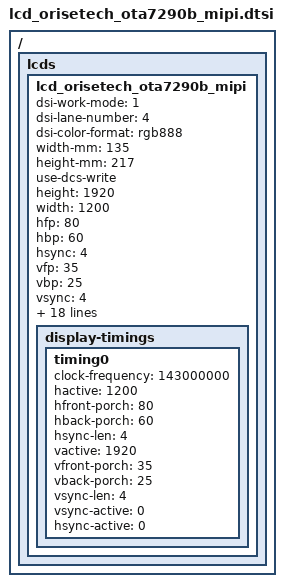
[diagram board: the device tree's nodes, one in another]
// SPDX-License-Identifier: GPL-2.0

/ { lcds: lcds {
	lcd_orisetech_ota7290b_mipi: lcd_orisetech_ota7290b_mipi {
		dsi-work-mode = <1>; /* video burst mode*/
		dsi-lane-number = <4>;
		dsi-color-format = "rgb888";
		width-mm = <135>;
		height-mm = <217>;
		use-dcs-write;

		/*mipi info*/
		height = <1920>;
		width = <1200>;
		hfp = <80>;
		hbp = <60>;
		hsync = <4>;
		vfp = <35>;
		vbp = <25>;
		vsync = <4>;
		fps = <55>;
		work-mode = <0>;
		rgb-mode = <3>;
		lane-number = <4>;
		phy-bit-clock = <1000000000>;
		phy-esc-clock = <76800000>;
		split-enable = <0>;
		eotp-enable = <0>;
		burst-mode = <2>;
		esd-check-enable = <0>;

		/* DSI_CMD, DSI_MODE, timeout, len, cmd */
		initial-command = [
			39 01 F0 01 11
			39 01 28 01 29
		];
		sleep-in-command = [
			39 01 78 01 28
			39 01 78 01 10
		];
		sleep-out-command = [
			39 01 96 01 11
			39 01 32 01 29
		];
		read-id-command = [
			37 01 00 01 05
			14 01 00 05 fb fc fd fe ff
		];

		display-timings {
			timing0 {
				clock-frequency = <143000000>;
				hactive = <1200>;
				hfront-porch = <80>;
				hback-porch = <60>;
				hsync-len = <4>;
				vactive = <1920>;
				vfront-porch = <35>;
				vback-porch = <25>;
				vsync-len = <4>;
				vsync-active = <0>;
				hsync-active = <0>;
			};
		};
	};
};};
